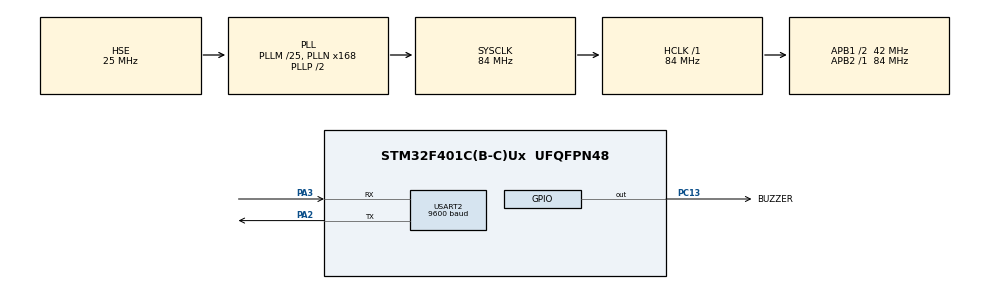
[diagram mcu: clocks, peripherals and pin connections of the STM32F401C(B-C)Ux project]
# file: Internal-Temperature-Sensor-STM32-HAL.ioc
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ADC1.Channel-6\#ChannelRegularConversion=ADC_CHANNEL_VREFINT
ADC1.Channel-8\#ChannelRegularConversion=ADC_CHANNEL_TEMPSENSOR
ADC1.ContinuousConvMode=ENABLE
ADC1.DMAContinuousRequests=ENABLE
ADC1.ExternalTrigConv=ADC_EXTERNALTRIGCONV_T3_TRGO
ADC1.InjNumberOfConversion=0
ADC1.NbrOfConversion=2
ADC1.NbrOfConversionFlag=1
ADC1.Rank-6\#ChannelRegularConversion=1
ADC1.Rank-8\#ChannelRegularConversion=2
ADC1.SamplingTime-6\#ChannelRegularConversion=ADC_SAMPLETIME_480CYCLES
ADC1.SamplingTime-8\#ChannelRegularConversion=ADC_SAMPLETIME_480CYCLES
ADC1.master=1
Dma.ADC1.0.Direction=DMA_PERIPH_TO_MEMORY
Dma.ADC1.0.FIFOMode=DMA_FIFOMODE_DISABLE
Dma.ADC1.0.Instance=DMA2_Stream0
Dma.ADC1.0.MemDataAlignment=DMA_MDATAALIGN_HALFWORD
Dma.ADC1.0.MemInc=DMA_MINC_ENABLE
Dma.ADC1.0.Mode=DMA_CIRCULAR
Dma.ADC1.0.PeriphDataAlignment=DMA_PDATAALIGN_HALFWORD
Dma.ADC1.0.PeriphInc=DMA_PINC_DISABLE
Dma.ADC1.0.Priority=DMA_PRIORITY_LOW
Dma.Request0=ADC1
Mcu.Family=STM32F4
Mcu.Name=STM32F401C(B-C)Ux
Mcu.Package=UFQFPN48
NVIC.ADC_IRQn=true\:0\:0\:false\:false\:true\:true\:true\:true
NVIC.DMA2_Stream0_IRQn=true\:0\:0\:false\:false\:true\:false\:true\:true
NVIC.PriorityGroup=NVIC_PRIORITYGROUP_4
PA13.Mode=Serial_Wire
PA13.Signal=SYS_JTMS-SWDIO
PA14.Mode=Serial_Wire
PA14.Signal=SYS_JTCK-SWCLK
PA2.Mode=Asynchronous
PA2.Signal=USART2_TX
PA3.Mode=Asynchronous
PA3.Signal=USART2_RX
PC13-ANTI_TAMP.GPIO_Label=BUZZER
PC13-ANTI_TAMP.Signal=GPIO_Output
PH0\ -\ OSC_IN.Mode=HSE-External-Oscillator
PH0\ -\ OSC_IN.Signal=RCC_OSC_IN
PH1\ -\ OSC_OUT.Mode=HSE-External-Oscillator
PH1\ -\ OSC_OUT.Signal=RCC_OSC_OUT
ProjectManager.HeapSize=0x200
ProjectManager.StackSize=0x400
ProjectManager.TargetToolchain=STM32CubeIDE
RCC.48MHZClocksFreq_Value=42000000
RCC.AHBFreq_Value=84000000
RCC.APB1CLKDivider=RCC_HCLK_DIV2
RCC.APB1Freq_Value=42000000
RCC.APB1TimFreq_Value=84000000
RCC.APB2Freq_Value=84000000
RCC.APB2TimFreq_Value=84000000
RCC.CortexFreq_Value=84000000
RCC.EnbaleCSS=true
RCC.HCLKFreq_Value=84000000
RCC.HSE_VALUE=25000000
RCC.HSI_VALUE=16000000
RCC.LSE_VALUE=32768
RCC.PLLM=25
RCC.PLLN=168
RCC.PLLSourceVirtual=RCC_PLLSOURCE_HSE
RCC.SYSCLKFreq_VALUE=84000000
RCC.SYSCLKSource=RCC_SYSCLKSOURCE_PLLCLK
RCC.VCOOutputFreq_Value=168000000
TIM3.Period=10000-1
TIM3.Prescaler=840-1
TIM3.TIM_MasterOutputTrigger=TIM_TRGO_UPDATE
USART2.BaudRate=9600
USART2.VirtualMode=VM_ASYNC
VP_ADC1_TempSens_Input.Mode=IN-TempSens
VP_ADC1_Vref_Input.Mode=IN-Vrefint
VP_TIM3_VS_ClockSourceINT.Mode=Internal
board=custom

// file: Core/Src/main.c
/* USER CODE BEGIN Header */
/**
  ******************************************************************************
  * @file           : main.c
  * @brief          : Main program body
  ******************************************************************************
  * @attention
  *
  * Copyright (c) 2022 STMicroelectronics.
  * All rights reserved.
  *
  * This software is licensed under terms that can be found in the LICENSE file
  * in the root directory of this software component.
  * If no LICENSE file comes with this software, it is provided AS-IS.
  *
  ******************************************************************************
  */
/* USER CODE END Header */
#include "main.h"

/* USER CODE BEGIN Includes */
#include "tmpsensor.h"

#include "uart_printf.h"
/* USER CODE END Includes */

/* USER CODE BEGIN PD */
#define DBG_UART 1
/* USER CODE END PD */

 ADC_HandleTypeDef hadc1;
DMA_HandleTypeDef hdma_adc1;

TIM_HandleTypeDef htim3;

UART_HandleTypeDef huart2;

/* USER CODE BEGIN PV */

typedef struct AdcValues{

	uint16_t Raw[2]; /* Raw values from ADC */
	double IntSensTmp; /* Temperature */

}adcval_t;

adcval_t Adc;

typedef struct Flags
{
	uint8_t ADCCMPLT;

}flag_t;

flag_t Flg = {0, };

/* USER CODE END PV */

void SystemClock_Config(void);
static void MX_GPIO_Init(void);
static void MX_DMA_Init(void);
static void MX_ADC1_Init(void);
static void MX_TIM3_Init(void);
static void MX_USART2_UART_Init(void);

int main(void)
{

  /* MCU Configuration--------------------------------------------------------*/

  /* Reset of all peripherals, Initializes the Flash interface and the Systick. */
  HAL_Init();

  /* Configure the system clock */
  SystemClock_Config();

  /* Initialize all configured peripherals */
  MX_GPIO_Init();
  MX_DMA_Init();
  MX_ADC1_Init();
  MX_TIM3_Init();
  MX_USART2_UART_Init();
  /* USER CODE BEGIN 2 */

  HAL_ADC_Start_DMA(&hadc1, (uint32_t*)Adc.Raw, 2);
  HAL_TIM_Base_Start(&htim3); /* This timer starts ADC conversion */

  /* USER CODE END 2 */

  /* Infinite loop */
  /* USER CODE BEGIN WHILE */
  while (1)
  {

		if (Flg.ADCCMPLT) /* Conversion completed, do calculations */
		{

			/* Temperature Sensor ADC-value, Reference Voltage ADC-value (if use) */
			Adc.IntSensTmp = TMPSENSOR_getTemperature(Adc.Raw[1], Adc.Raw[0]);

			#if(DBG_UART) /* Send data with UART2 */
			UART_Printf_Dbg("Reference: Adc.Raw[0] = %u\r\n", Adc.Raw[0]);
			UART_Printf_Dbg("Sensor: Adc.Raw[1] = %u\r\n", Adc.Raw[1]);
			UART_Printf_Dbg("Temperature: Adc.IntSensTmp = %.2f℃\r\n", Adc.IntSensTmp);
			#endif

			#if(DBG_UART) /* Delay */
			HAL_Delay(250);
			#endif

			Flg.ADCCMPLT = 0; /* Nullify flag */
		}

    /* USER CODE END WHILE */

  }
}

void SystemClock_Config(void)
{
  RCC_OscInitTypeDef RCC_OscInitStruct = {0};
  RCC_ClkInitTypeDef RCC_ClkInitStruct = {0};

  /** Configure the main internal regulator output voltage
  */
  __HAL_RCC_PWR_CLK_ENABLE();
  __HAL_PWR_VOLTAGESCALING_CONFIG(PWR_REGULATOR_VOLTAGE_SCALE2);

  /** Initializes the RCC Oscillators according to the specified parameters
  * in the RCC_OscInitTypeDef structure.
  */
  RCC_OscInitStruct.OscillatorType = RCC_OSCILLATORTYPE_HSE;
  RCC_OscInitStruct.HSEState = RCC_HSE_ON;
  RCC_OscInitStruct.PLL.PLLState = RCC_PLL_ON;
  RCC_OscInitStruct.PLL.PLLSource = RCC_PLLSOURCE_HSE;
  RCC_OscInitStruct.PLL.PLLM = 25;
  RCC_OscInitStruct.PLL.PLLN = 168;
  RCC_OscInitStruct.PLL.PLLP = RCC_PLLP_DIV2;
  RCC_OscInitStruct.PLL.PLLQ = 4;
  if (HAL_RCC_OscConfig(&RCC_OscInitStruct) != HAL_OK)
  {
    Error_Handler();
  }

  /** Initializes the CPU, AHB and APB buses clocks
  */
  RCC_ClkInitStruct.ClockType = RCC_CLOCKTYPE_HCLK|RCC_CLOCKTYPE_SYSCLK
                              |RCC_CLOCKTYPE_PCLK1|RCC_CLOCKTYPE_PCLK2;
  RCC_ClkInitStruct.SYSCLKSource = RCC_SYSCLKSOURCE_PLLCLK;
  RCC_ClkInitStruct.AHBCLKDivider = RCC_SYSCLK_DIV1;
  RCC_ClkInitStruct.APB1CLKDivider = RCC_HCLK_DIV2;
  RCC_ClkInitStruct.APB2CLKDivider = RCC_HCLK_DIV1;

  if (HAL_RCC_ClockConfig(&RCC_ClkInitStruct, FLASH_LATENCY_2) != HAL_OK)
  {
    Error_Handler();
  }

  /** Enables the Clock Security System
  */
  HAL_RCC_EnableCSS();
}

static void MX_ADC1_Init(void)
{

  ADC_ChannelConfTypeDef sConfig = {0};

  /** Configure the global features of the ADC (Clock, Resolution, Data Alignment and number of conversion)
  */
  hadc1.Instance = ADC1;
  hadc1.Init.ClockPrescaler = ADC_CLOCK_SYNC_PCLK_DIV4;
  hadc1.Init.Resolution = ADC_RESOLUTION_12B;
  hadc1.Init.ScanConvMode = ENABLE;
  hadc1.Init.ContinuousConvMode = ENABLE;
  hadc1.Init.DiscontinuousConvMode = DISABLE;
  hadc1.Init.ExternalTrigConvEdge = ADC_EXTERNALTRIGCONVEDGE_RISING;
  hadc1.Init.ExternalTrigConv = ADC_EXTERNALTRIGCONV_T3_TRGO;
  hadc1.Init.DataAlign = ADC_DATAALIGN_RIGHT;
  hadc1.Init.NbrOfConversion = 2;
  hadc1.Init.DMAContinuousRequests = ENABLE;
  hadc1.Init.EOCSelection = ADC_EOC_SINGLE_CONV;
  if (HAL_ADC_Init(&hadc1) != HAL_OK)
  {
    Error_Handler();
  }

  /** Configure for the selected ADC regular channel its corresponding rank in the sequencer and its sample time.
  */
  sConfig.Channel = ADC_CHANNEL_VREFINT;
  sConfig.Rank = 1;
  sConfig.SamplingTime = ADC_SAMPLETIME_480CYCLES;
  if (HAL_ADC_ConfigChannel(&hadc1, &sConfig) != HAL_OK)
  {
    Error_Handler();
  }

  /** Configure for the selected ADC regular channel its corresponding rank in the sequencer and its sample time.
  */
  sConfig.Channel = ADC_CHANNEL_TEMPSENSOR;
  sConfig.Rank = 2;
  if (HAL_ADC_ConfigChannel(&hadc1, &sConfig) != HAL_OK)
  {
    Error_Handler();
  }

}

static void MX_TIM3_Init(void)
{

  TIM_ClockConfigTypeDef sClockSourceConfig = {0};
  TIM_MasterConfigTypeDef sMasterConfig = {0};

  htim3.Instance = TIM3;
  htim3.Init.Prescaler = 840-1;
  htim3.Init.CounterMode = TIM_COUNTERMODE_UP;
  htim3.Init.Period = 10000-1;
  htim3.Init.ClockDivision = TIM_CLOCKDIVISION_DIV1;
  htim3.Init.AutoReloadPreload = TIM_AUTORELOAD_PRELOAD_DISABLE;
  if (HAL_TIM_Base_Init(&htim3) != HAL_OK)
  {
    Error_Handler();
  }
  sClockSourceConfig.ClockSource = TIM_CLOCKSOURCE_INTERNAL;
  if (HAL_TIM_ConfigClockSource(&htim3, &sClockSourceConfig) != HAL_OK)
  {
    Error_Handler();
  }
  sMasterConfig.MasterOutputTrigger = TIM_TRGO_UPDATE;
  sMasterConfig.MasterSlaveMode = TIM_MASTERSLAVEMODE_DISABLE;
  if (HAL_TIMEx_MasterConfigSynchronization(&htim3, &sMasterConfig) != HAL_OK)
  {
    Error_Handler();
  }

}

static void MX_USART2_UART_Init(void)
{

  huart2.Instance = USART2;
  huart2.Init.BaudRate = 9600;
  huart2.Init.WordLength = UART_WORDLENGTH_8B;
  huart2.Init.StopBits = UART_STOPBITS_1;
  huart2.Init.Parity = UART_PARITY_NONE;
  huart2.Init.Mode = UART_MODE_TX_RX;
  huart2.Init.HwFlowCtl = UART_HWCONTROL_NONE;
  huart2.Init.OverSampling = UART_OVERSAMPLING_16;
  if (HAL_UART_Init(&huart2) != HAL_OK)
  {
    Error_Handler();
  }

}

static void MX_DMA_Init(void)
{

  /* DMA controller clock enable */
  __HAL_RCC_DMA2_CLK_ENABLE();

  /* DMA interrupt init */
  /* DMA2_Stream0_IRQn interrupt configuration */
  HAL_NVIC_SetPriority(DMA2_Stream0_IRQn, 0, 0);
  HAL_NVIC_EnableIRQ(DMA2_Stream0_IRQn);

}

static void MX_GPIO_Init(void)
{
  GPIO_InitTypeDef GPIO_InitStruct = {0};

  /* GPIO Ports Clock Enable */
  __HAL_RCC_GPIOC_CLK_ENABLE();
  __HAL_RCC_GPIOH_CLK_ENABLE();
  __HAL_RCC_GPIOA_CLK_ENABLE();

  /*Configure GPIO pin Output Level */
  HAL_GPIO_WritePin(BUZZER_GPIO_Port, BUZZER_Pin, GPIO_PIN_RESET);

  /*Configure GPIO pin : BUZZER_Pin */
  GPIO_InitStruct.Pin = BUZZER_Pin;
  GPIO_InitStruct.Mode = GPIO_MODE_OUTPUT_PP;
  GPIO_InitStruct.Pull = GPIO_NOPULL;
  GPIO_InitStruct.Speed = GPIO_SPEED_FREQ_LOW;
  HAL_GPIO_Init(BUZZER_GPIO_Port, &GPIO_InitStruct);

}

/* USER CODE BEGIN 4 */

void HAL_ADC_ConvCpltCallback(ADC_HandleTypeDef* hadc)
{
    if(hadc->Instance == ADC1) /* Check if the interrupt comes from ACD1 */
    {
    	/* Set flag to true */
    	Flg.ADCCMPLT = 255;
    }
}

/* USER CODE END 4 */

void Error_Handler(void)
{
  __disable_irq();
  while (1)
  {
  }
}
